# platform_designer_hps_system_hps_0_hps register map
Vendor: default_vendor.com; File version: 0.0
Registers are 32-bit, read-write, reset 0x0 unless marked. A register's access mark holds for its fields unless they carry their own. Offsets are from the block's base; [hi:lo] are bit positions.

## sdr — Address map for the SDRAM Interface registers
Base 0xFFC20000
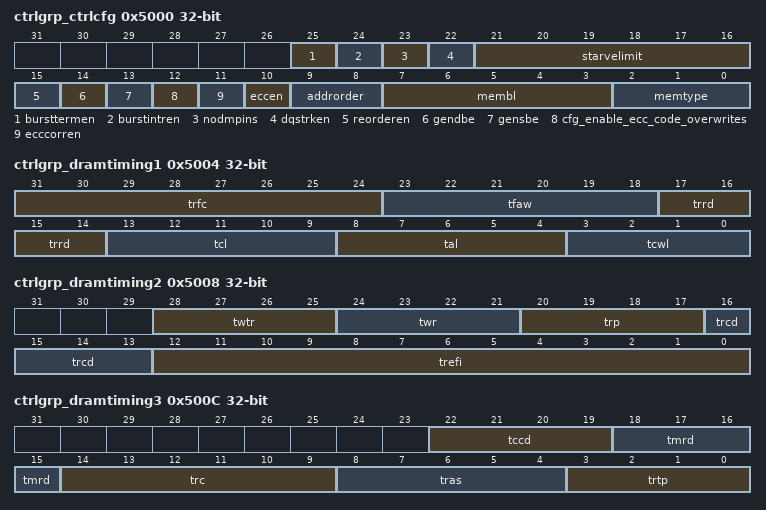
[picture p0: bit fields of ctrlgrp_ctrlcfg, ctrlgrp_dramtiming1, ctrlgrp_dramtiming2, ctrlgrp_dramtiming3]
0x5000 ctrlgrp_ctrlcfg (reset mask 0xF8000000) — The Controller Configuration Register determines the behavior of the controller.
  [25] bursttermen — Set to a one to enable the controller to issue burst terminate commands. This must only be set when the DRAM memory type is LPDDR2.
  [24] burstintren — Set to a one to enable the controller to issue burst interrupt commands. This must only be set when the DRAM memory type is LPDDR2.
  [23] nodmpins — Set to a one to enable DRAM operation if no DM pins are connected.
  [22] dqstrken — Enables DQS tracking in the PHY.
  [21:16] starvelimit — Specifies the number of DRAM burst transactions an individual transaction will allow to reorder ahead of it before its priority is raised in the memory controller.
  [15] reorderen — This bit controls whether the controller can re-order operations to optimize SDRAM bandwidth. It should generally be set to a one.
  [14] gendbe — Enable the deliberate insertion of double bit errors in data written to memory. This should only be used for testing purposes.
  [13] gensbe — Enable the deliberate insertion of single bit errors in data written to memory. This should only be used for testing purposes.
  [12] cfg_enable_ecc_code_overwrites — Set to a one to enable ECC overwrites. ECC overwrites occur when a correctable ECC error is seen and cause a new read/modify/write to be scheduled for that location to clear the ECC error.
  [11] ecccorren — Enable auto correction of the read data returned when single bit error is detected.
  [10] eccen — Enable the generation and checking of ECC. This bit must only be set if the memory connected to the SDRAM interface is 24 or 40 bits wide. If you set this, you must clear the useeccasdata field in the staticcfg register.
  [9:8] addrorder — Selects the order for address interleaving. Programming this field with different values gives different mappings between the AXI or Avalon-MM address and the SDRAM address. Program this field with the following binary values to select the ordering. "00" - chip, row, bank, column, "01" - chip, bank, row, column, "10"-row, chip, bank, column
  [7:3] membl — Configures burst length as a static decimal value. Legal values are valid for JEDEC allowed DRAM values for the DRAM selected in cfg_type. For DDR3, this should be programmed with 8 (binary "01000"), for DDR2 it can be either 4 or 8 depending on the exact DRAM chip. LPDDR2 can be programmed with 4, 8, or 16 and LPDDR can be programmed with 2, 4, or 8. You must also program the membl field in the staticcfg register.
  [2:0] memtype — Selects memory type. Program this field with one of the following binary values, "001" for DDR2 SDRAM, "010" for DDR3 SDRAM, "011" for LPDDR1 SDRAM or "100" for LPDDR2 SDRAM.
0x5004 ctrlgrp_dramtiming1 reset not defined — This register implements JEDEC standardized timing parameters. It should be programmed in clock cycles, for the value specified by the memory vendor.
  [31:24] trfc — The refresh cycle timing parameter.
  [23:18] tfaw — The four-activate window timing parameter.
  [17:14] trrd — The activate to activate, different banks timing parameter.
  [13:9] tcl — Memory read latency.
  [8:4] tal — Memory additive latency.
  [3:0] tcwl — Memory write latency.
0x5008 ctrlgrp_dramtiming2 (reset mask 0xE0000000) — This register implements JEDEC standardized timing parameters. It should be programmed in clock cycles, for the value specified by the memory vendor.
  [28:25] twtr — The write to read timing parameter.
  [24:21] twr — The write recovery timing.
  [20:17] trp — The precharge to activate timing parameter.
  [16:13] trcd — The activate to read/write timing parameter.
  [12:0] trefi — The refresh interval timing parameter.
0x500C ctrlgrp_dramtiming3 (reset mask 0xFF800000) — This register implements JEDEC standardized timing parameters. It should be programmed in clock cycles, for the value specified by the memory vendor.
  [22:19] tccd — The CAS to CAS delay time.
  [18:15] tmrd — Mode register timing parameter.
  [14:9] trc — The activate to activate timing parameter.
  [8:4] tras — The activate to precharge timing parameter.
  [3:0] trtp — The read to precharge timing parameter.
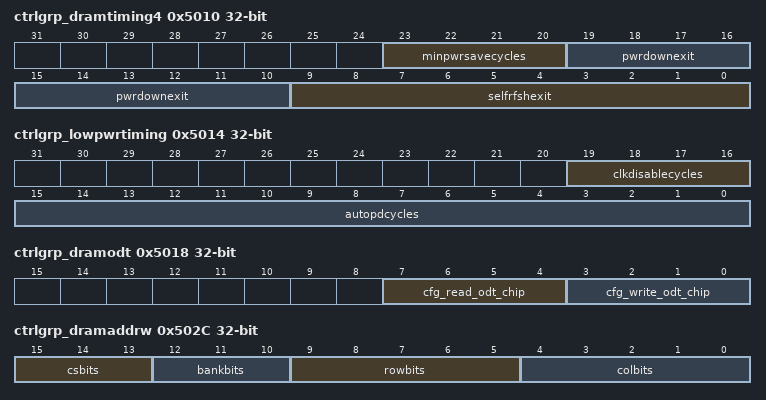
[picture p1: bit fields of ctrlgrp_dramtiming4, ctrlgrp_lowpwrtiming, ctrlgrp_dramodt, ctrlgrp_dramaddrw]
0x5010 ctrlgrp_dramtiming4 (reset mask 0xFF000000) — This register implements JEDEC standardized timing parameters. It should be programmed in clock cycles, for the value specified by the memory vendor.
  [23:20] minpwrsavecycles — The minimum number of cycles to stay in a low power state. This applies to both power down and self-refresh and should be set to the greater of tPD and tCKESR.
  [19:10] pwrdownexit — The power down exit cycles, tXPDLL.
  [9:0] selfrfshexit — The self refresh exit cycles, tXS.
0x5014 ctrlgrp_lowpwrtiming (reset mask 0xFFF00000) — This register controls the behavior of the low power logic in the controller.
  [19:16] clkdisablecycles — Set to a the number of clocks after the execution of an self-refresh to stop the clock. This register is generally set based on PHY design latency and should generally not be changed.
  [15:0] autopdcycles — The number of idle clock cycles after which the controller should place the memory into power-down mode.
0x5018 ctrlgrp_dramodt (reset mask 0xFFFFFF00) — This register controls which ODT pin is asserted during reads or writes. Bits [1:0] control which ODT pin is asserted during to accesses to chip select 0, bits [3:2] which ODT pin is asserted during accesses to chip select 1. For example, a value of "1001" will cause ODT[0] to be asserted for accesses to CS[0], and ODT[1] to be asserted for access to CS[1] pin. Set this to "0001" if there is only one chip select available.
  [7:4] cfg_read_odt_chip — This register controls which ODT pin is asserted during reads.
  [3:0] cfg_write_odt_chip — This register controls which ODT pin is asserted during writes.
0x502C ctrlgrp_dramaddrw (reset mask 0xFFFF0000) — This register configures the width of the various address fields of the DRAM. The values specified in this register must match the memory devices being used.
  [15:13] csbits — The number of chip select address bits for the memory devices in your memory interface.
  [12:10] bankbits — The number of bank address bits for the memory devices in your memory interface.
  [9:5] rowbits — The number of row address bits for the memory devices in your memory interface.
  [4:0] colbits — The number of column address bits for the memory devices in your memory interface.
0x5030 ctrlgrp_dramifwidth (reset mask 0xFFFFFF00)
  [7:0] ifwidth — This register controls the interface width of the SDRAM interface, including any bits used for ECC. For example, for a 32-bit interface with ECC, program this register with 0x28. You must also program the ctrlwidth register.
0x5034 ctrlgrp_dramdevwidth (reset mask 0xFFFFFFF0)
  [3:0] devwidth — This register specifies the width of the physical DRAM chips, for example 8 or 16.
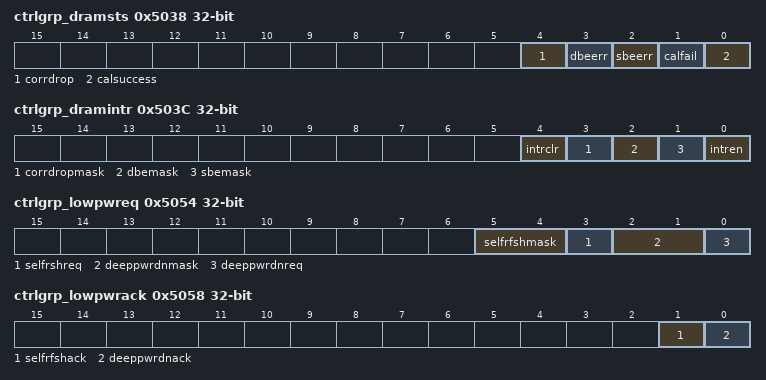
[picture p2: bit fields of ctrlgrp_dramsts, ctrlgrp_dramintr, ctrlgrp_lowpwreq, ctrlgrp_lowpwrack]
0x5038 ctrlgrp_dramsts (reset mask 0xFFFFFFE0) — This register provides the status of the calibration and ECC logic.
  [4] corrdrop — This bit will be set to 1 if there any auto-corrections have been dropped.
  [3] dbeerr — This bit will be set to 1 if there have been any ECC double bit errors detected.
  [2] sbeerr — This bit will be set to 1 if there have been any ECC single bit errors detected.
  [1] calfail — This bit will be set to 1 if the PHY was unable to calibrate.
  [0] calsuccess — This bit will be set to 1 if the PHY was able to successfully calibrate.
0x503C ctrlgrp_dramintr (reset mask 0xFFFFFFE0)
  [4] intrclr — Writing to this self-clearing bit clears the interrupt signal. Writing to this bit also clears the error count and error address registers.
  [3] corrdropmask — Set this bit to a one to mask interrupts for an ECC correction write back needing to be dropped. This indicates a burst of memory errors in a short period of time.
  [2] dbemask — Mask the double bit error interrupt.
  [1] sbemask — Mask the single bit error interrupt.
  [0] intren — Enable the interrupt output.
0x5040 ctrlgrp_sbecount (reset mask 0xFFFFFF00)
  [7:0] count — Reports the number of single bit errors that have occurred since the status register counters were last cleared.
0x5044 ctrlgrp_dbecount (reset mask 0xFFFFFF00)
  [7:0] count — Reports the number of double bit errors that have occurred since the status register counters were last cleared.
0x5048 ctrlgrp_erraddr reset not defined
  [31:0] addr — The address of the most recent ECC error.
0x504C ctrlgrp_dropcount (reset mask 0xFFFFFF00)
  [7:0] corrdropcount — This gives the count of the number of ECC write back transactions dropped due to the internal FIFO overflowing.
0x5050 ctrlgrp_dropaddr reset not defined
  [31:0] corrdropaddr — This register gives the last address which was dropped.
0x5054 ctrlgrp_lowpwreq (reset mask 0xFFFFFFC0) — This register instructs the controller to put the DRAM into a power down state. Note that some commands are only valid for certain memory types.
  [5:4] selfrfshmask — Write a one to each bit of this field to have a self refresh request apply to both chips.
  [3] selfrshreq — Write a one to this bit to request the RAM be put into a self refresh state. This bit is treated as a static value so the RAM will remain in self-refresh as long as this register bit is set to a one. This power down mode can be selected for all DRAMs supported by the controller.
  [2:1] deeppwrdnmask — Write ones to this register to select which DRAM chip selects will be powered down. Typical usage is to set both of these bits when deeppwrdnreq is set but the controller does support putting a single chip into deep power down and keeping the other chip running.
  [0] deeppwrdnreq — Write a one to this bit to request a deep power down. This bit should only be written with LPDDR2 DRAMs, DDR3 DRAMs do not support deep power down.
0x5058 ctrlgrp_lowpwrack (reset mask 0xFFFFFFFC) — This register gives the status of the power down commands requested by the Low Power Control register.
  [1] selfrfshack — This bit is a one to indicate that the controller is in a self-refresh state.
  [0] deeppwrdnack — This bit is set to a one after a deep power down has been executed
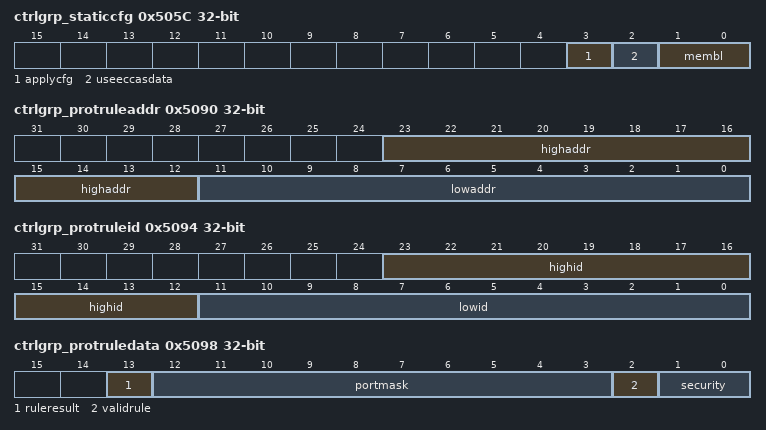
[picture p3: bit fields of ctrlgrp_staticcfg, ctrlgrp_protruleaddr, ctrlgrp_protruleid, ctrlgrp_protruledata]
0x505C ctrlgrp_staticcfg (reset mask 0xFFFFFFF0) — This register controls configuration values which cannot be updated while transactions are flowing. You should write once to this register with the membl and eccen fields set to your desired configuration, and then write to the register again with membl and eccen and the applycfg bit set. The applycfg bit is write only.
  [3] applycfg — Write with this bit set to apply all the settings loaded in SDR registers to the memory interface. This bit is write-only and always returns 0 if read.
  [2] useeccasdata — This field allows the FPGA ports to directly access the extra data bits that are normally used to hold the ECC code. The interface width must be set to 24 or 40 in the dramifwidth register. If you set this, you must clear the eccen field in the ctrlcfg register.
  [1:0] membl — This field specifies the DRAM burst length. Write the following values to set the a burst length appropriate for the specific DRAM being used. "00" for burst length 2, "01" for burst length 4, "10" for burst length 8. If you set this, you must also set the membl field in the ctrlcfg register.
0x5060 ctrlgrp_ctrlwidth (reset mask 0xFFFFFFFC) — This register controls the width of the physical DRAM interface.
  [1:0] ctrlwidth — Specifies controller DRAM interface width, with the following encoding. "00" for 8-bit, "01" for 16-bit (no ECC) or 24-bit (ECC enabled), "10" for 32-bit (no ECC) or 40-bit (ECC enabled). You must also program the dramifwidth register.
0x507C ctrlgrp_portcfg (reset mask 0xFFF00000) — This register should be set to a zero in any bit which corresponds to a port which does mostly sequential memory accesses. For ports with highly random accesses, the bit should be set to a one.
  [19:10] autopchen — One bit per control port. Set bit N to a 1 to have the controller request an automatic precharge following bus command completion (close the row automatically). Set to a zero to request that the controller attempt to keep a row open. For random dominated operations this register should be set to a 1 for all active ports.
0x5080 ctrlgrp_fpgaportrst (reset mask 0xFFFFC000) — This register implements functionality to allow the CPU to control when the MPFE will enable the ports to the FPGA fabric.
  [13:0] portrstn — This register should be written to with a 1 to enable the selected FPGA port to exit reset. Writing a bit to a zero will stretch the port reset until the register is written. Read data ports are connected to bits 3:0, with read data port 0 at bit 0 to read data port 3 at bit 3. Write data ports 0 to 3 are mapped to 4 to 7, with write data port 0 connected to bit 4 to write data port 3 at bit 7. Command ports are connected to bits 8 to 13, with command port 0 at bit 8 to command port 5 at bit 13. Expected usage would be to set all the bits at the same time but setting some bits to a zero and others to a one is supported.
0x508C ctrlgrp_protportdefault (reset mask 0xFFFFFC00) — This register controls the default protection assignment for a port. Ports which have explicit rules which define regions which are illegal to access should set the bits to pass by default. Ports which have explicit rules which define legal areas should set the bit to force all transactions to fail. Leaving this register to all zeros should be used for systems which do not desire any protection from the memory controller.
  [9:0] portdefault — Determines the default action for a transactions from a port. Set a bit to a zero to indicate that all accesses from the port should pass by default, set a bit to a one if the default protection is to fail the access.
0x5090 ctrlgrp_protruleaddr (reset mask 0xFF000000) — This register is used to control the memory protection for port 0 transactions. Address ranges can either be used to allow access to memory regions or disallow access to memory regions. If trustzone is being used, access can be enabled for protected transactions or disabled for unprotected transactions. The default state of this register is to allow all access. Address values used for protection are only physical addresses.
  [23:12] highaddr — Upper 12 bits of the address for a check. Address is compared to be greater than or equal to the address of a transaction. Note that since AXI transactions cannot cross a 4K byte boundary, the transaction start and transaction end address must also fall within the same 1MByte block pointed to by this address pointer.
  [11:0] lowaddr — Lower 12 bits of the address for a check. Address is compared to be less than or equal to the address of a transaction. Note that since AXI transactions cannot cross a 4K byte boundary, the transaction start and transaction end address must also fall within the same 1MByte block pointed to by this address pointer.
0x5094 ctrlgrp_protruleid (reset mask 0xFF000000)
  [23:12] highid — AxID for the protection rule. Incoming AxID needs to be less than or equal to this value. For all AxIDs from a port, AxID high should be programmed to all ones.
  [11:0] lowid — AxID for the protection rule. Incoming AxID needs to be greater than or equal to this value. For all AxIDs from a port, AxID high should be programmed to all ones.
0x5098 ctrlgrp_protruledata (reset mask 0xFFFFC000)
  [13] ruleresult — Set this bit to a one to force a protection failure, zero to allow the access the succeed
  [12:3] portmask — Set bit x to a one to have this rule apply to port x, set bit x to a zero to have the rule not apply to a port. Note that port 0-port 5 are the FPGA fabric ports, port 6 is L3 read, port 7 is CPU read, port 8 is L3 write, port 9 is CPU write.
  [2] validrule — Set to bit to a one to make a rule valid, set to a zero to invalidate a rule.
  [1:0] security — A value of 2'b00 will make the rule apply to secure transactions. A value of 2'b01 will make the rule apply to non-secure transactions. A value of 2'b10 or 2'b11 will make the rule apply to secure and non-secure transactions.
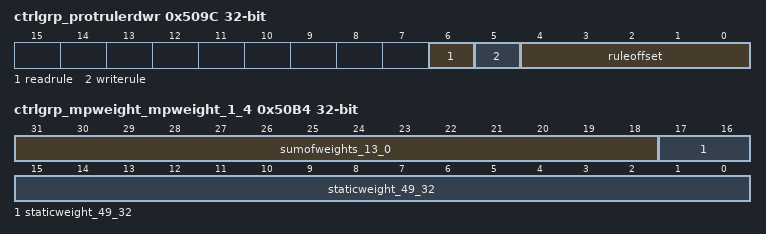
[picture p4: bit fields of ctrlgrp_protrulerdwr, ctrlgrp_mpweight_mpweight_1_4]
0x509C ctrlgrp_protrulerdwr (reset mask 0xFFFFFF80) — This register is used to perform read and write operations to the internal protection table.
  [6] readrule — Write to this bit to have the memory_prot_data register loaded with the value from the internal protection table at offset. Table value will be loaded before a rdy is returned so read data from the register will be correct for any follow-on reads to the memory_prot_data register.
  [5] writerule — Write to this bit to have the memory_prot_data register to the table at the offset specified by port_offset. Bit automatically clears after a single cycle and the write operation is complete.
  [4:0] ruleoffset — This field defines which of the 20 rules in the protection table you want to read or write.
0x50A0 ctrlgrp_qoslowpri (reset mask 0xFFF00000) — This register controls the mapping of AXI4 QOS received from the FPGA fabric to the internal priority used for traffic prioritization.
  [19:0] lowpriorityval — This 20 bit field is a 2 bit field for each of the 10 ports. The field used for each port in this register controls the priority used for a port
0x50A4 ctrlgrp_qoshighpri (reset mask 0xFFF00000)
  [19:0] highpriorityval — This 20 bit field is a 2 bit field for each of the 10 ports. The field used for each port in this register controls the priority used for a port
0x50A8 ctrlgrp_qospriorityen (reset mask 0xFFFFFC00)
  [9:0] priorityen — This 10 bit field is set to a one to enable QOS usage for a port.
0x50AC ctrlgrp_mppriority (reset mask 0xC0000000) — This register is used to configure the DRAM burst operation scheduling.
  [29:0] userpriority — Set absolute user priority of the port. Each port is represented by a 3 bit value, 000=lowest priority, 111=highest priority. Port 0 is bits 2:0. Port number offset corresponds to the control port assignment.
0x50B0 ctrlgrp_mpweight_mpweight_0_4 reset not defined — This register is used to configure the DRAM burst operation scheduling.
  [31:0] staticweight_31_0 — Set static weight of the port. Each port is programmed with a 5 bit value. Port 0 is bits 4:0, port 1 is bits 9:5, up to port 9 being bits 49:45
0x50B4 ctrlgrp_mpweight_mpweight_1_4 reset not defined — This register is used to configure the DRAM burst operation scheduling.
  [31:18] sumofweights_13_0 — Set the sum of static weights for particular user priority. This register is used as part of the deficit round robin implementation. It should be set to the sum of the weights for the ports
  [17:0] staticweight_49_32 — Set static weight of the port. Each port is programmed with a 5 bit value. Port 0 is bits 4:0, port 1 is bits 9:5, up to port 9 being bits 49:45
0x50B8 ctrlgrp_mpweight_mpweight_2_4 reset not defined — This register is used to configure the DRAM burst operation scheduling.
  [31:0] sumofweights_45_14 — Set the sum of static weights for particular user priority. This register is used as part of the deficit round robin implementation. It should be set to the sum of the weights for the ports
0x50BC ctrlgrp_mpweight_mpweight_3_4 (reset mask 0xFFFC0000) — This register is used to configure the DRAM burst operation scheduling.
  [17:0] sumofweights_63_46 — Set the sum of static weights for particular user priority. This register is used as part of the deficit round robin implementation. It should be set to the sum of the weights for the ports
0x50E0 ctrlgrp_remappriority (reset mask 0xFFFFFF00) — This register controls the priority for transactions in the controller command pool.
  [7:0] priorityremap — Set bit N of this register to the value to a one to enable the controller command pool priority bit of a transaction from MPFE priority N
